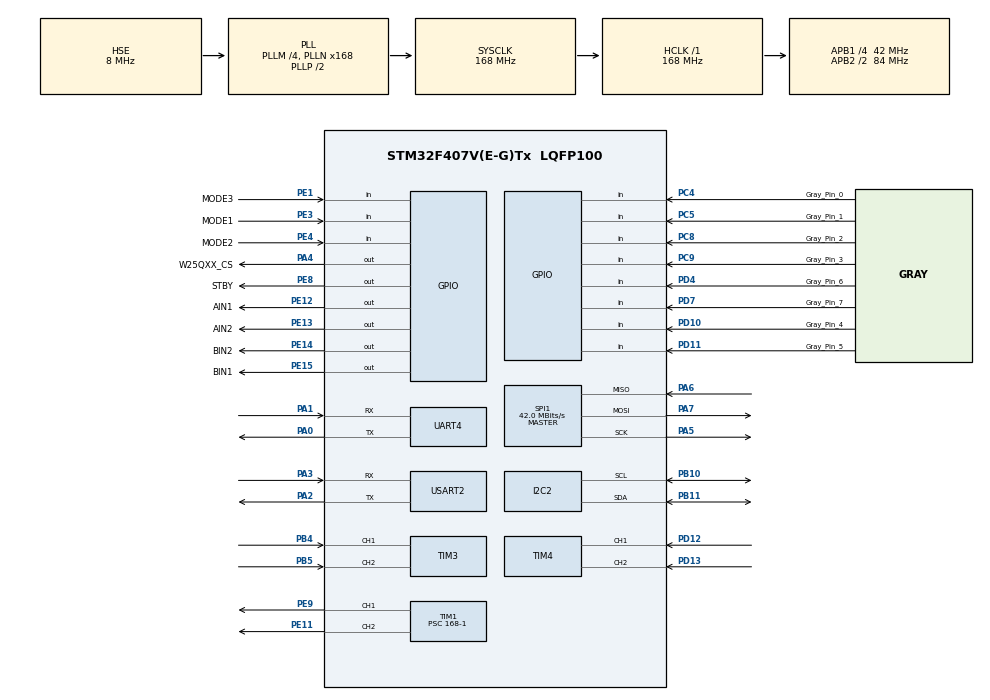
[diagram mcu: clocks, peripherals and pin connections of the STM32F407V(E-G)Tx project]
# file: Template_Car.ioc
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Dma.Request0=USART2_RX
Dma.Request1=UART4_RX
Dma.UART4_RX.1.Direction=DMA_PERIPH_TO_MEMORY
Dma.UART4_RX.1.FIFOMode=DMA_FIFOMODE_DISABLE
Dma.UART4_RX.1.Instance=DMA1_Stream2
Dma.UART4_RX.1.MemDataAlignment=DMA_MDATAALIGN_BYTE
Dma.UART4_RX.1.MemInc=DMA_MINC_ENABLE
Dma.UART4_RX.1.Mode=DMA_NORMAL
Dma.UART4_RX.1.PeriphDataAlignment=DMA_PDATAALIGN_BYTE
Dma.UART4_RX.1.PeriphInc=DMA_PINC_DISABLE
Dma.UART4_RX.1.Priority=DMA_PRIORITY_HIGH
Dma.USART2_RX.0.Direction=DMA_PERIPH_TO_MEMORY
Dma.USART2_RX.0.FIFOMode=DMA_FIFOMODE_DISABLE
Dma.USART2_RX.0.Instance=DMA1_Stream5
Dma.USART2_RX.0.MemDataAlignment=DMA_MDATAALIGN_BYTE
Dma.USART2_RX.0.MemInc=DMA_MINC_ENABLE
Dma.USART2_RX.0.Mode=DMA_NORMAL
Dma.USART2_RX.0.PeriphDataAlignment=DMA_PDATAALIGN_BYTE
Dma.USART2_RX.0.PeriphInc=DMA_PINC_DISABLE
Dma.USART2_RX.0.Priority=DMA_PRIORITY_VERY_HIGH
Mcu.Family=STM32F4
Mcu.Name=STM32F407V(E-G)Tx
Mcu.Package=LQFP100
NVIC.DMA1_Stream2_IRQn=true\:0\:0\:false\:false\:true\:false\:true\:true
NVIC.DMA1_Stream5_IRQn=true\:0\:0\:true\:false\:true\:false\:true\:true
NVIC.PriorityGroup=NVIC_PRIORITYGROUP_4
NVIC.TIM2_IRQn=true\:0\:0\:true\:false\:true\:true\:true\:true
NVIC.TIM3_IRQn=true\:1\:0\:true\:false\:true\:true\:true\:true
NVIC.TIM4_IRQn=true\:1\:0\:true\:false\:true\:true\:true\:true
NVIC.UART4_IRQn=true\:0\:0\:false\:false\:true\:true\:true\:true
NVIC.USART2_IRQn=true\:2\:0\:true\:false\:true\:true\:true\:true
PA0-WKUP.Mode=Asynchronous
PA0-WKUP.Signal=UART4_TX
PA1.Mode=Asynchronous
PA1.Signal=UART4_RX
PA13.Mode=Serial_Wire
PA13.Signal=SYS_JTMS-SWDIO
PA14.Mode=Serial_Wire
PA14.Signal=SYS_JTCK-SWCLK
PA2.Mode=Asynchronous
PA2.Signal=USART2_TX
PA3.Mode=Asynchronous
PA3.Signal=USART2_RX
PA4.GPIO_Label=W25QXX_CS
PA4.Signal=GPIO_Output
PA5.Mode=Full_Duplex_Master
PA5.Signal=SPI1_SCK
PA6.Mode=Full_Duplex_Master
PA6.Signal=SPI1_MISO
PA7.Mode=Full_Duplex_Master
PA7.Signal=SPI1_MOSI
PB10.Mode=I2C
PB10.Signal=I2C2_SCL
PB11.Mode=I2C
PB11.Signal=I2C2_SDA
PB4.Signal=S_TIM3_CH1
PB5.Signal=S_TIM3_CH2
PC14-OSC32_IN.Mode=LSE-External-Oscillator
PC14-OSC32_IN.Signal=RCC_OSC32_IN
PC15-OSC32_OUT.Mode=LSE-External-Oscillator
PC15-OSC32_OUT.Signal=RCC_OSC32_OUT
PC4.GPIO_Label=Gray_Pin_0
PC4.GPIO_PuPd=GPIO_PULLUP
PC4.Signal=GPIO_Input
PC5.GPIO_Label=Gray_Pin_1
PC5.GPIO_PuPd=GPIO_PULLUP
PC5.Signal=GPIO_Input
PC8.GPIO_Label=Gray_Pin_2
PC8.GPIO_PuPd=GPIO_PULLUP
PC8.Signal=GPIO_Input
PC9.GPIO_Label=Gray_Pin_3
PC9.GPIO_PuPd=GPIO_PULLUP
PC9.Signal=GPIO_Input
PD10.GPIO_Label=Gray_Pin_4
PD10.GPIO_PuPd=GPIO_PULLUP
PD10.Signal=GPIO_Input
PD11.GPIO_Label=Gray_Pin_5
PD11.GPIO_PuPd=GPIO_PULLUP
PD11.Signal=GPIO_Input
PD12.Signal=S_TIM4_CH1
PD13.Signal=S_TIM4_CH2
PD4.GPIO_Label=Gray_Pin_6
PD4.GPIO_PuPd=GPIO_PULLUP
PD4.Signal=GPIO_Input
PD7.GPIO_Label=Gray_Pin_7
PD7.GPIO_PuPd=GPIO_PULLUP
PD7.Signal=GPIO_Input
PE1.GPIO_Label=MODE3
PE1.GPIO_PuPd=GPIO_PULLUP
PE1.Signal=GPIO_Input
PE11.Signal=S_TIM1_CH2
PE12.GPIO_Label=AIN1
PE12.Signal=GPIO_Output
PE13.GPIO_Label=AIN2
PE13.Signal=GPIO_Output
PE14.GPIO_Label=BIN2
PE14.Signal=GPIO_Output
PE15.GPIO_Label=BIN1
PE15.Signal=GPIO_Output
PE3.GPIO_Label=MODE1
PE3.GPIO_PuPd=GPIO_PULLUP
PE3.Signal=GPIO_Input
PE4.GPIO_Label=MODE2
PE4.GPIO_PuPd=GPIO_PULLUP
PE4.Signal=GPIO_Input
PE8.GPIO_Label=STBY
PE8.PinState=GPIO_PIN_RESET
PE8.Signal=GPIO_Output
PE9.Signal=S_TIM1_CH1
PH0-OSC_IN.Mode=HSE-External-Oscillator
PH0-OSC_IN.Signal=RCC_OSC_IN
PH1-OSC_OUT.Mode=HSE-External-Oscillator
PH1-OSC_OUT.Signal=RCC_OSC_OUT
ProjectManager.HeapSize=0x400
ProjectManager.StackSize=0x800
ProjectManager.TargetToolchain=MDK-ARM V5.32
RCC.48MHZClocksFreq_Value=84000000
RCC.AHBFreq_Value=168000000
RCC.APB1CLKDivider=RCC_HCLK_DIV4
RCC.APB1Freq_Value=42000000
RCC.APB1TimFreq_Value=84000000
RCC.APB2CLKDivider=RCC_HCLK_DIV2
RCC.APB2Freq_Value=84000000
RCC.APB2TimFreq_Value=168000000
RCC.CortexFreq_Value=168000000
RCC.HCLKFreq_Value=168000000
RCC.HSE_VALUE=8000000
RCC.HSI_VALUE=16000000
RCC.PLLM=4
RCC.PLLN=168
RCC.PLLSourceVirtual=RCC_PLLSOURCE_HSE
RCC.SYSCLKFreq_VALUE=168000000
RCC.SYSCLKSource=RCC_SYSCLKSOURCE_PLLCLK
RCC.VCOOutputFreq_Value=336000000
SH.S_TIM1_CH1.0=TIM1_CH1,PWM Generation1 CH1
SH.S_TIM1_CH2.0=TIM1_CH2,PWM Generation2 CH2
SH.S_TIM3_CH1.0=TIM3_CH1,Encoder_Interface
SH.S_TIM3_CH2.0=TIM3_CH2,Encoder_Interface
SH.S_TIM4_CH1.0=TIM4_CH1,Encoder_Interface
SH.S_TIM4_CH2.0=TIM4_CH2,Encoder_Interface
SPI1.CalculateBaudRate=42.0 MBits/s
SPI1.Direction=SPI_DIRECTION_2LINES
SPI1.Mode=SPI_MODE_MASTER
SPI1.VirtualType=VM_MASTER
TIM1.Channel-PWM\ Generation1\ CH1=TIM_CHANNEL_1
TIM1.Channel-PWM\ Generation2\ CH2=TIM_CHANNEL_2
TIM1.Period=1000-1
TIM1.Prescaler=168-1
TIM2.Period=1000-1
TIM2.Prescaler=84-1
TIM3.EncoderMode=TIM_ENCODERMODE_TI12
TIM4.EncoderMode=TIM_ENCODERMODE_TI12
UART4.VirtualMode=Asynchronous
USART2.VirtualMode=VM_ASYNC
VP_TIM1_VS_ClockSourceINT.Mode=Internal
VP_TIM2_VS_ClockSourceINT.Mode=Internal
board=custom

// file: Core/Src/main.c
/* USER CODE BEGIN Header */
/**
  ******************************************************************************
  * @file           : main.c
  * @brief          : Main program body
  ******************************************************************************
  * @attention
  *
  * Copyright (c) 2025 STMicroelectronics.
  * All rights reserved.
  *
  * This software is licensed under terms that can be found in the LICENSE file
  * in the root directory of this software component.
  * If no LICENSE file comes with this software, it is provided AS-IS.
  *
  ******************************************************************************
  */
/* USER CODE END Header */
#include "main.h"
#include "dma.h"
#include "i2c.h"
#include "spi.h"
#include "tim.h"
#include "usart.h"
#include "gpio.h"

/* USER CODE BEGIN Includes */
#include "bsp_system.h"
/* USER CODE END Includes */

void SystemClock_Config(void);

int main(void)
{

  /* MCU Configuration--------------------------------------------------------*/

  /* Reset of all peripherals, Initializes the Flash interface and the Systick. */
  HAL_Init();

  /* Configure the system clock */
  SystemClock_Config();

  /* Initialize all configured peripherals */
  MX_GPIO_Init();
  MX_DMA_Init();
  MX_USART2_UART_Init();
  MX_TIM1_Init();
  MX_TIM2_Init();
  MX_TIM3_Init();
  MX_TIM4_Init();
  MX_I2C2_Init();
  MX_SPI1_Init();
  MX_UART4_Init();
  /* USER CODE BEGIN 2 */
  W25QXX_Init();
  My_Uart_Init();
  HAL_Delay(200);
  OLED_Init();
  Encoder_Init();
  Motor_Init();
  button_system_init();
  PID_Init();
  Scheduler_Init();
  /* USER CODE END 2 */

  /* Infinite loop */
  /* USER CODE BEGIN WHILE */
  while (1)
  {
      Scheduler_Run();
    /* USER CODE END WHILE */

  }
}

void SystemClock_Config(void)
{
  RCC_OscInitTypeDef RCC_OscInitStruct = {0};
  RCC_ClkInitTypeDef RCC_ClkInitStruct = {0};

  /** Configure the main internal regulator output voltage
  */
  __HAL_RCC_PWR_CLK_ENABLE();
  __HAL_PWR_VOLTAGESCALING_CONFIG(PWR_REGULATOR_VOLTAGE_SCALE1);

  /** Initializes the RCC Oscillators according to the specified parameters
  * in the RCC_OscInitTypeDef structure.
  */
  RCC_OscInitStruct.OscillatorType = RCC_OSCILLATORTYPE_HSE;
  RCC_OscInitStruct.HSEState = RCC_HSE_ON;
  RCC_OscInitStruct.PLL.PLLState = RCC_PLL_ON;
  RCC_OscInitStruct.PLL.PLLSource = RCC_PLLSOURCE_HSE;
  RCC_OscInitStruct.PLL.PLLM = 4;
  RCC_OscInitStruct.PLL.PLLN = 168;
  RCC_OscInitStruct.PLL.PLLP = RCC_PLLP_DIV2;
  RCC_OscInitStruct.PLL.PLLQ = 4;
  if (HAL_RCC_OscConfig(&RCC_OscInitStruct) != HAL_OK)
  {
    Error_Handler();
  }

  /** Initializes the CPU, AHB and APB buses clocks
  */
  RCC_ClkInitStruct.ClockType = RCC_CLOCKTYPE_HCLK|RCC_CLOCKTYPE_SYSCLK
                              |RCC_CLOCKTYPE_PCLK1|RCC_CLOCKTYPE_PCLK2;
  RCC_ClkInitStruct.SYSCLKSource = RCC_SYSCLKSOURCE_PLLCLK;
  RCC_ClkInitStruct.AHBCLKDivider = RCC_SYSCLK_DIV1;
  RCC_ClkInitStruct.APB1CLKDivider = RCC_HCLK_DIV4;
  RCC_ClkInitStruct.APB2CLKDivider = RCC_HCLK_DIV2;

  if (HAL_RCC_ClockConfig(&RCC_ClkInitStruct, FLASH_LATENCY_5) != HAL_OK)
  {
    Error_Handler();
  }
}

void Error_Handler(void)
{
  __disable_irq();
  while (1)
  {
  }
}
